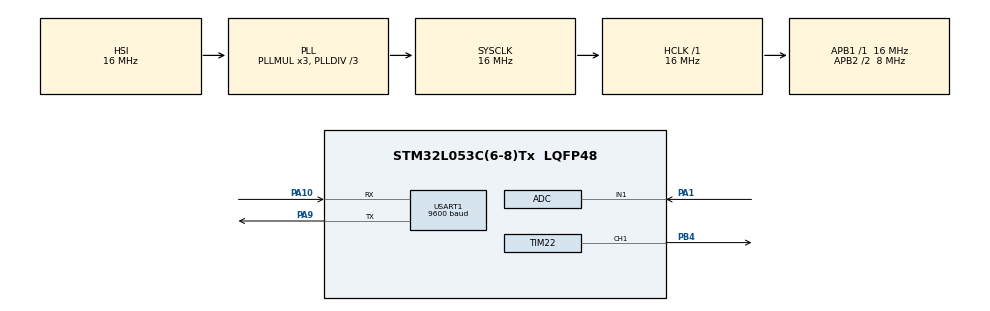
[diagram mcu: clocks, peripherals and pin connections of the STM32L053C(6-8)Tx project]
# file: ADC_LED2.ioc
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ADC.ContinuousConvMode=ENABLE
ADC.SamplingTime=ADC_SAMPLETIME_160CYCLES_5
Mcu.Family=STM32L0
Mcu.Name=STM32L053C(6-8)Tx
Mcu.Package=LQFP48
PA1.Mode=IN1
PA1.Signal=ADC_IN1
PA10.Mode=Asynchronous
PA10.Signal=USART1_RX
PA13.Mode=Serial_Wire
PA13.Signal=SYS_SWDIO
PA14.Mode=Serial_Wire
PA14.Signal=SYS_SWCLK
PA9.GPIO_Speed=GPIO_SPEED_FREQ_VERY_HIGH
PA9.Mode=Asynchronous
PA9.Signal=USART1_TX
PB4.Signal=S_TIM22_CH1
PC14-OSC32_IN.Mode=LSE-External-Oscillator
PC14-OSC32_IN.Signal=RCC_OSC32_IN
PC15-OSC32_OUT.Mode=LSE-External-Oscillator
PC15-OSC32_OUT.Signal=RCC_OSC32_OUT
PH0-OSC_IN.Mode=HSE-External-Oscillator
PH0-OSC_IN.Signal=RCC_OSC_IN
PH1-OSC_OUT.Mode=HSE-External-Oscillator
PH1-OSC_OUT.Signal=RCC_OSC_OUT
ProjectManager.HeapSize=0x200
ProjectManager.StackSize=0x400
ProjectManager.TargetToolchain=MDK-ARM V5.32
RCC.AHBFreq_Value=16000000
RCC.APB1Freq_Value=16000000
RCC.APB1TimFreq_Value=16000000
RCC.APB2CLKDivider=RCC_HCLK_DIV2
RCC.APB2Freq_Value=8000000
RCC.APB2TimFreq_Value=16000000
RCC.HCLKFreq_Value=16000000
RCC.HSE_VALUE=8000000
RCC.HSI16_VALUE=16000000
RCC.HSI48MClockSelection=RCC_USBCLKSOURCE_HSI48
RCC.HSI48_VALUE=48000000
RCC.HSI_VALUE=16000000
RCC.MSI_VALUE=2097000
RCC.PLLDIV=RCC_PLLDIV_3
RCC.RTCClockSelectionVirtual=RCC_RTCCLKSOURCE_LSE
RCC.SYSCLKFreq_VALUE=16000000
RCC.SYSCLKSource=RCC_SYSCLKSOURCE_PLLCLK
RCC.VCOOutputFreq_Value=48000000
SH.S_TIM22_CH1.0=TIM22_CH1,PWM Generation1 CH1
TIM22.Channel-PWM\ Generation1\ CH1=TIM_CHANNEL_1
TIM22.Period=320
TIM22.Prescaler=0
USART1.BaudRate=9600
USART1.VirtualMode-Asynchronous=VM_ASYNC
VP_TIM22_VS_ClockSourceINT.Mode=Internal
board=STM32L0538-DISCO

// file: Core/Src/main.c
/* USER CODE BEGIN Header */
/**
  ******************************************************************************
  * @file           : main.c
  * @brief          : Main program body
  ******************************************************************************
  * @attention
  *
  * Copyright (c) 2022 STMicroelectronics.
  * All rights reserved.
  *
  * This software is licensed under terms that can be found in the LICENSE file
  * in the root directory of this software component.
  * If no LICENSE file comes with this software, it is provided AS-IS.
  *
  ******************************************************************************
  */
/* USER CODE END Header */
#include "main.h"

/* USER CODE BEGIN Includes */

//#include <stdio.h>

/* USER CODE END Includes */

ADC_HandleTypeDef hadc;

TIM_HandleTypeDef htim22;

UART_HandleTypeDef huart1;

/* USER CODE BEGIN PV */

uint16_t adc_value;
uint8_t TxMessage[]="UART Transmit Example\r\n";

/* USER CODE END PV */

void SystemClock_Config(void);
static void MX_GPIO_Init(void);
static void MX_ADC_Init(void);
static void MX_USART1_UART_Init(void);
static void MX_TIM22_Init(void);

int main(void)
{

  /* MCU Configuration--------------------------------------------------------*/

  /* Reset of all peripherals, Initializes the Flash interface and the Systick. */
  HAL_Init();

  /* Configure the system clock */
  SystemClock_Config();

  /* Initialize all configured peripherals */
  MX_GPIO_Init();
  MX_ADC_Init();
  MX_USART1_UART_Init();
  MX_TIM22_Init();
  /* USER CODE BEGIN 2 */

		HAL_TIM_PWM_Start(&htim22,TIM_CHANNEL_1);
	//TIM2->CCR1 = 16;

  /* USER CODE END 2 */

  /* Infinite loop */
  /* USER CODE BEGIN WHILE */
  while (1)
  {
		HAL_ADC_Start(&hadc);
		HAL_Delay(100);
		adc_value=HAL_ADC_GetValue(&hadc);
		HAL_ADC_PollForConversion(&hadc,4090);

			__HAL_TIM_SET_COMPARE(&htim22,TIM_CHANNEL_1,adc_value);

    /* USER CODE END WHILE */

    /* USER CODE BEGIN 3 */

		HAL_UART_Transmit(&huart1,(uint8_t*)TxMessage,sizeof(TxMessage),HAL_MAX_DELAY);
		HAL_Delay(500);
		//HAL_StatusTypeDef HAL_UART_Transmit(UART_HandleTypeDef *huart, uint8_t *pData, uint16_t Size, uint32_t Timeout)

  }
  /* USER CODE END 3 */
}

void SystemClock_Config(void)
{
  RCC_OscInitTypeDef RCC_OscInitStruct = {0};
  RCC_ClkInitTypeDef RCC_ClkInitStruct = {0};
  RCC_PeriphCLKInitTypeDef PeriphClkInit = {0};

  /** Configure the main internal regulator output voltage
  */
  __HAL_PWR_VOLTAGESCALING_CONFIG(PWR_REGULATOR_VOLTAGE_SCALE1);

  /** Initializes the RCC Oscillators according to the specified parameters
  * in the RCC_OscInitTypeDef structure.
  */
  RCC_OscInitStruct.OscillatorType = RCC_OSCILLATORTYPE_HSI;
  RCC_OscInitStruct.HSIState = RCC_HSI_ON;
  RCC_OscInitStruct.HSICalibrationValue = RCC_HSICALIBRATION_DEFAULT;
  RCC_OscInitStruct.PLL.PLLState = RCC_PLL_ON;
  RCC_OscInitStruct.PLL.PLLSource = RCC_PLLSOURCE_HSI;
  RCC_OscInitStruct.PLL.PLLMUL = RCC_PLLMUL_3;
  RCC_OscInitStruct.PLL.PLLDIV = RCC_PLLDIV_3;
  if (HAL_RCC_OscConfig(&RCC_OscInitStruct) != HAL_OK)
  {
    Error_Handler();
  }

  /** Initializes the CPU, AHB and APB buses clocks
  */
  RCC_ClkInitStruct.ClockType = RCC_CLOCKTYPE_HCLK|RCC_CLOCKTYPE_SYSCLK
                              |RCC_CLOCKTYPE_PCLK1|RCC_CLOCKTYPE_PCLK2;
  RCC_ClkInitStruct.SYSCLKSource = RCC_SYSCLKSOURCE_PLLCLK;
  RCC_ClkInitStruct.AHBCLKDivider = RCC_SYSCLK_DIV1;
  RCC_ClkInitStruct.APB1CLKDivider = RCC_HCLK_DIV1;
  RCC_ClkInitStruct.APB2CLKDivider = RCC_HCLK_DIV2;

  if (HAL_RCC_ClockConfig(&RCC_ClkInitStruct, FLASH_LATENCY_0) != HAL_OK)
  {
    Error_Handler();
  }
  PeriphClkInit.PeriphClockSelection = RCC_PERIPHCLK_USART1;
  PeriphClkInit.Usart1ClockSelection = RCC_USART1CLKSOURCE_PCLK2;
  if (HAL_RCCEx_PeriphCLKConfig(&PeriphClkInit) != HAL_OK)
  {
    Error_Handler();
  }
}

static void MX_ADC_Init(void)
{

  ADC_ChannelConfTypeDef sConfig = {0};

  /** Configure the global features of the ADC (Clock, Resolution, Data Alignment and number of conversion)
  */
  hadc.Instance = ADC1;
  hadc.Init.OversamplingMode = DISABLE;
  hadc.Init.ClockPrescaler = ADC_CLOCK_SYNC_PCLK_DIV2;
  hadc.Init.Resolution = ADC_RESOLUTION_12B;
  hadc.Init.SamplingTime = ADC_SAMPLETIME_160CYCLES_5;
  hadc.Init.ScanConvMode = ADC_SCAN_DIRECTION_FORWARD;
  hadc.Init.DataAlign = ADC_DATAALIGN_RIGHT;
  hadc.Init.ContinuousConvMode = ENABLE;
  hadc.Init.DiscontinuousConvMode = DISABLE;
  hadc.Init.ExternalTrigConvEdge = ADC_EXTERNALTRIGCONVEDGE_NONE;
  hadc.Init.ExternalTrigConv = ADC_SOFTWARE_START;
  hadc.Init.DMAContinuousRequests = DISABLE;
  hadc.Init.EOCSelection = ADC_EOC_SINGLE_CONV;
  hadc.Init.Overrun = ADC_OVR_DATA_PRESERVED;
  hadc.Init.LowPowerAutoWait = DISABLE;
  hadc.Init.LowPowerFrequencyMode = DISABLE;
  hadc.Init.LowPowerAutoPowerOff = DISABLE;
  if (HAL_ADC_Init(&hadc) != HAL_OK)
  {
    Error_Handler();
  }

  /** Configure for the selected ADC regular channel to be converted.
  */
  sConfig.Channel = ADC_CHANNEL_1;
  sConfig.Rank = ADC_RANK_CHANNEL_NUMBER;
  if (HAL_ADC_ConfigChannel(&hadc, &sConfig) != HAL_OK)
  {
    Error_Handler();
  }

}

static void MX_TIM22_Init(void)
{

  TIM_ClockConfigTypeDef sClockSourceConfig = {0};
  TIM_MasterConfigTypeDef sMasterConfig = {0};
  TIM_OC_InitTypeDef sConfigOC = {0};

  htim22.Instance = TIM22;
  htim22.Init.Prescaler = 0;
  htim22.Init.CounterMode = TIM_COUNTERMODE_UP;
  htim22.Init.Period = 320;
  htim22.Init.ClockDivision = TIM_CLOCKDIVISION_DIV1;
  htim22.Init.AutoReloadPreload = TIM_AUTORELOAD_PRELOAD_DISABLE;
  if (HAL_TIM_Base_Init(&htim22) != HAL_OK)
  {
    Error_Handler();
  }
  sClockSourceConfig.ClockSource = TIM_CLOCKSOURCE_INTERNAL;
  if (HAL_TIM_ConfigClockSource(&htim22, &sClockSourceConfig) != HAL_OK)
  {
    Error_Handler();
  }
  if (HAL_TIM_PWM_Init(&htim22) != HAL_OK)
  {
    Error_Handler();
  }
  sMasterConfig.MasterOutputTrigger = TIM_TRGO_RESET;
  sMasterConfig.MasterSlaveMode = TIM_MASTERSLAVEMODE_DISABLE;
  if (HAL_TIMEx_MasterConfigSynchronization(&htim22, &sMasterConfig) != HAL_OK)
  {
    Error_Handler();
  }
  sConfigOC.OCMode = TIM_OCMODE_PWM1;
  sConfigOC.Pulse = 0;
  sConfigOC.OCPolarity = TIM_OCPOLARITY_HIGH;
  sConfigOC.OCFastMode = TIM_OCFAST_DISABLE;
  if (HAL_TIM_PWM_ConfigChannel(&htim22, &sConfigOC, TIM_CHANNEL_1) != HAL_OK)
  {
    Error_Handler();
  }
  HAL_TIM_MspPostInit(&htim22);

}

static void MX_USART1_UART_Init(void)
{

  huart1.Instance = USART1;
  huart1.Init.BaudRate = 9600;
  huart1.Init.WordLength = UART_WORDLENGTH_8B;
  huart1.Init.StopBits = UART_STOPBITS_1;
  huart1.Init.Parity = UART_PARITY_NONE;
  huart1.Init.Mode = UART_MODE_TX_RX;
  huart1.Init.HwFlowCtl = UART_HWCONTROL_NONE;
  huart1.Init.OverSampling = UART_OVERSAMPLING_16;
  huart1.Init.OneBitSampling = UART_ONE_BIT_SAMPLE_DISABLE;
  huart1.AdvancedInit.AdvFeatureInit = UART_ADVFEATURE_NO_INIT;
  if (HAL_UART_Init(&huart1) != HAL_OK)
  {
    Error_Handler();
  }

}

static void MX_GPIO_Init(void)
{

  /* GPIO Ports Clock Enable */
  __HAL_RCC_GPIOC_CLK_ENABLE();
  __HAL_RCC_GPIOH_CLK_ENABLE();
  __HAL_RCC_GPIOA_CLK_ENABLE();
  __HAL_RCC_GPIOB_CLK_ENABLE();

}

void Error_Handler(void)
{
  __disable_irq();
  while (1)
  {
  }
}
